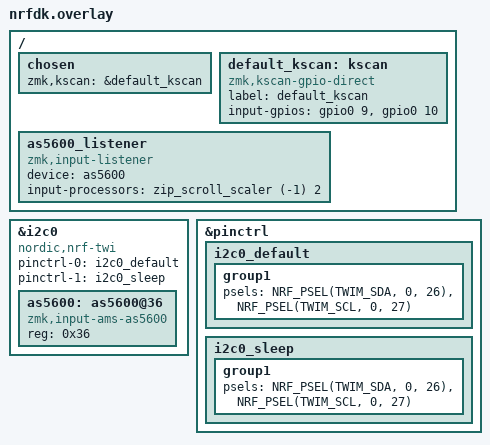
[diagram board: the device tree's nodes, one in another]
#include <input/processors.dtsi>

&i2c0 {
    compatible = "nordic,nrf-twi";
    pinctrl-0 = <&i2c0_default>;
    pinctrl-1 = <&i2c0_sleep>;
    pinctrl-names = "default", "sleep";
    status = "okay";

    as5600: as5600@36{
        compatible = "zmk,input-ams-as5600";
        reg = <0x36>;
        status = "okay";
    };
};

&pinctrl {
    i2c0_default: i2c0_default {
        group1 {
            psels = <NRF_PSEL(TWIM_SDA, 0, 26)>, <NRF_PSEL(TWIM_SCL, 0, 27)>;
        };
    };
    i2c0_sleep: i2c0_sleep {
        group1 {
            psels = <NRF_PSEL(TWIM_SDA, 0, 26)>, <NRF_PSEL(TWIM_SCL, 0, 27)>;
        };
    };
};

/ {
    chosen {
        zmk,kscan = &default_kscan;
    };

    default_kscan: kscan {
        compatible = "zmk,kscan-gpio-direct";
        label = "default_kscan";

        input-gpios = 
            <&gpio0 9 GPIO_ACTIVE_HIGH>,
            <&gpio0 10 GPIO_ACTIVE_HIGH>
            ;
    };
    
    as5600_listener: as5600_listener {
        compatible = "zmk,input-listener";
        device = <&as5600>;
        input-processors = <&zip_scroll_scaler (-1) 2>;
    };
};
